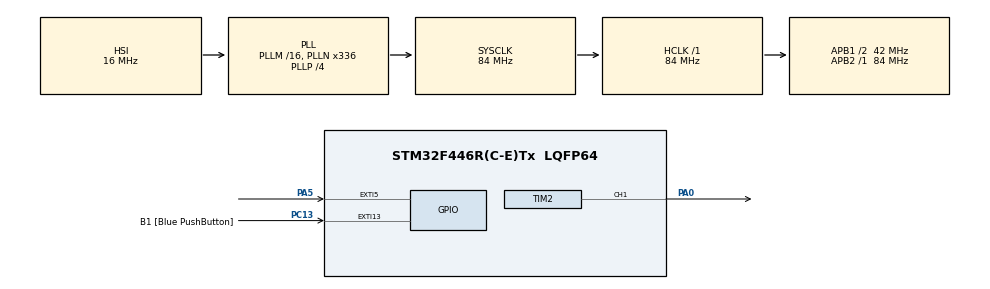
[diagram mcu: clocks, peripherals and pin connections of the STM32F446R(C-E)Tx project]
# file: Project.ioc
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Mcu.Family=STM32F4
Mcu.Name=STM32F446R(C-E)Tx
Mcu.Package=LQFP64
NVIC.PriorityGroup=NVIC_PRIORITYGROUP_0
PA0-WKUP.Signal=S_TIM2_CH1_ETR
PA13.GPIO_Label=TMS
PA13.Signal=SYS_JTMS-SWDIO
PA14.GPIO_Label=TCK
PA14.Signal=SYS_JTCK-SWCLK
PA2.GPIO_Label=USART_TX
PA2.Signal=USART2_TX
PA3.GPIO_Label=USART_RX
PA3.Signal=USART2_RX
PA5.Signal=GPXTI5
PB3.GPIO_Label=SWO
PB3.Signal=SYS_JTDO-SWO
PC13.GPIO_Label=B1 [Blue PushButton]
PC13.GPIO_ModeDefaultEXTI=GPIO_MODE_IT_FALLING
PC13.Signal=GPXTI13
PC14-OSC32_IN.Signal=RCC_OSC32_IN
PC15-OSC32_OUT.Signal=RCC_OSC32_OUT
PH0-OSC_IN.Mode=HSE-External-Oscillator
PH0-OSC_IN.Signal=RCC_OSC_IN
PH1-OSC_OUT.Mode=HSE-External-Oscillator
PH1-OSC_OUT.Signal=RCC_OSC_OUT
ProjectManager.HeapSize=0x200
ProjectManager.StackSize=0x400
ProjectManager.TargetToolchain=STM32CubeIDE
RCC.AHBFreq_Value=84000000
RCC.APB1CLKDivider=RCC_HCLK_DIV2
RCC.APB1Freq_Value=42000000
RCC.APB1TimFreq_Value=84000000
RCC.APB2Freq_Value=84000000
RCC.APB2TimFreq_Value=84000000
RCC.CortexFreq_Value=84000000
RCC.FLatency-AdvancedSettings=FLASH_LATENCY_2
RCC.HCLKFreq_Value=84000000
RCC.HSE_VALUE=8000000
RCC.HSI_VALUE=16000000
RCC.LSE_VALUE=32768
RCC.PLLN=336
RCC.PLLP=RCC_PLLP_DIV4
RCC.SYSCLKFreq_VALUE=84000000
RCC.SYSCLKSource=RCC_SYSCLKSOURCE_PLLCLK
RCC.USBFreq_Value=168000000
RCC.VCOOutputFreq_Value=336000000
SH.S_TIM2_CH1_ETR.0=TIM2_CH1,PWM Generation1 CH1
TIM2.AutoReloadPreload=TIM_AUTORELOAD_PRELOAD_ENABLE
TIM2.Channel-PWM\ Generation1\ CH1=TIM_CHANNEL_1
TIM2.Period=65535
VP_TIM2_VS_ClockSourceINT.Mode=Internal
board=NUCLEO-F446RE

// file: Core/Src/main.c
/* USER CODE BEGIN Header */
/**
 ******************************************************************************
 * @file           : main.c
 * @brief          : Main program body
 ******************************************************************************
 * @attention
 *
 * Copyright (c) 2024 STMicroelectronics.
 * All rights reserved.
 *
 * This software is licensed under terms that can be found in the LICENSE file
 * in the root directory of this software component.
 * If no LICENSE file comes with this software, it is provided AS-IS.
 *
 ******************************************************************************
 */
/* USER CODE END Header */
#include "main.h"

/* USER CODE BEGIN Includes */
#include <stdio.h>

/* USER CODE END Includes */

/* USER CODE BEGIN PTD */
#define BIP_PT 200 //BIP d'un point
#define BIP_TIRET 600//bip d'un tiret(Equiv 3 pts)*
#define ESC_ENTRE_LTR 600 //espacement entre 2 lettres
#define ESC_ENTRE_ELT 200 //espacement entre 2 element de la lettre
#define ESC_MOTS 1400 //espacement entre 2 mots = 7pts

/* USER CODE END PTD */

TIM_HandleTypeDef htim2;
char *morseCode[] = { "-.-.-----.", // !
		".-..-.", // "
		"..-..-.", // # (Na)
		"...-..-", // $
		"..-..-.", // % (Na)
		".-...", // &
		".----.", // '
		"-.--.", // (
		"-.--.-", // )
		"..-..-.", // * (Na)
		".-.-.", // +
		"--..--", // ,
		"-....-", // -
		".-.-.-", // .
		"-..-.", // /
		"-----", // 0
		".----", // 1
		"..---", // 2
		"...--", // 3
		"....-", // 4
		".....", // 5
		"-....", // 6
		"--...", // 7
		"---..", // 8
		"----.", // 9
		"---...", // :
		"-.-.-.", // ;
		".-..-.", // < (Na)
		"-...-", // =
		".-..-.", // > (Na)
		"..--..", // ?
		".--.-.", // @
		".-", // A
		"-...", // B
		"-.-.", // C
		"-..", // D
		".", // E
		"..-.", // F
		"--.", // G
		"....", // H
		"..", // I
		".---", // J
		"-.-", // K
		".-..", // L
		"--", // M
		"-.", // N
		"---", // O
		".--.", // P
		".-.", // Q
		".-.", // R
		"...", // S
		"-", // T
		"..-", // U
		"...-", // V
		".--", // W
		"-..-", // X
		"-.--", // Y
		"--..", // Z
		".-..-.", // [ (Na)
		".-..-.", // \ (Na)
		".-..-.", // ] (Na)
		".-..-.", // ^ (Na)
		"..--.-", // _
		".-..-.", // ` (Na)
		".-", // a
		"-...", // b
		"-.-.", // c
		"-..", // d
		".", // e
		"..-.", // f
		"--.", // g
		"....", // h
		"..", // i
		".---", // j
		"-.-", // k
		".-..", // l
		"--", // m
		"-.", // n
		"---", // o
		".--.", // p
		".-.", // q
		".-.", // r
		"...", // s
		"-", // t
		"..-", // u
		"...-", // v
		".--", // w
		"-..-", // x
		"-.--", // y
		"--..", // z
		};

void SystemClock_Config(void);
static void MX_GPIO_Init(void);
static void MX_TIM2_Init(void);
int conversion_ASCII(char caractere);
void interpretation(char c);

/* USER CODE BEGIN 0 */
uint8_t value = 0; // the value for the duty cycle

/* USER CODE END 0 */

int main(void) {

	/* MCU Configuration--------------------------------------------------------*/

	/* Reset of all peripherals, Initializes the Flash interface and the Systick. */
	HAL_Init();

	/* Configure the system clock */
	SystemClock_Config();

	/* Initialize all configured peripherals */
	MX_GPIO_Init();
	MX_TIM2_Init();
	/* USER CODE BEGIN 2 */
	HAL_TIM_PWM_Start(&htim2, TIM_CHANNEL_1);
	char *phrase = "ceci est un teste";
	/* USER CODE END 2 */

	/* Infinite loop */
	while (1) {
		for (int i = 0; phrase[i] != '\0'; i++) {
			interpretation(phrase[i]);
			HAL_Delay(ESC_ENTRE_LTR);
		}
		/* USER CODE BEGIN 3 */
	}

//
	/* USER CODE END 3 */
}

int conversion_ASCII(char caractere) {
	// Soustrait le code ASCII du caractère par le code ASCII du point d'exclamation ('!')
	// Cela permet de mapper les caractères ASCII à partir du point d'exclamation (33) au début du tableau codeMorse[]
	// Ainsi, '!' deviendra 0, et les caractères suivants seront convertis en valeurs croissantes
	return caractere - '!';
}
void interpretation(char c) {
	if (c == ' ') { //on a atteint la fin du mot
		htim2.Instance->CCR1 = 0; //on init a 0 pour arreter la génération de signaux sonores
		HAL_Delay(ESC_MOTS);
	} else {
		int index = conversion_ASCII(c); //on appelle la fct pour obtenir l'index du caractere dans le tableau
		char *morse = codeMorse[index]; //on recup la sequence la sequence de code morse du caractere
		for (int i = 0; morse[i] != '\0'; i++) { //\0 veux dire le caractere de fin de chaine(1er elt du code ASCII)
			if (morse[i] == '.') {
				htim2.Instance->CCR1 = 65535; // Active la sortie sonore
				HAL_Delay(BIP_PT); //On attends la durée correspondant a un point
				htim2.Instance->CCR1 = 0; // Désactive la sortie sonore
				HAL_Delay(ESC_ENTRE_ELT);
			} else if (morse[i] == '-') {
				htim2.Instance->CCR1 = 65535;
				HAL_Delay(BIP_TIRET);
				htim2.Instance->CCR1 = 0;
				HAL_Delay(ESC_ENTRE_ELT);
			}
		}
	}
}
void SystemClock_Config(void) {
	RCC_OscInitTypeDef RCC_OscInitStruct = { 0 };
	RCC_ClkInitTypeDef RCC_ClkInitStruct = { 0 };

	/** Configure the main internal regulator output voltage
	 */
	__HAL_RCC_PWR_CLK_ENABLE();
	__HAL_PWR_VOLTAGESCALING_CONFIG(PWR_REGULATOR_VOLTAGE_SCALE3);

	/** Initializes the RCC Oscillators according to the specified parameters
	 * in the RCC_OscInitTypeDef structure.
	 */
	RCC_OscInitStruct.OscillatorType = RCC_OSCILLATORTYPE_HSI;
	RCC_OscInitStruct.HSIState = RCC_HSI_ON;
	RCC_OscInitStruct.HSICalibrationValue = RCC_HSICALIBRATION_DEFAULT;
	RCC_OscInitStruct.PLL.PLLState = RCC_PLL_ON;
	RCC_OscInitStruct.PLL.PLLSource = RCC_PLLSOURCE_HSI;
	RCC_OscInitStruct.PLL.PLLM = 16;
	RCC_OscInitStruct.PLL.PLLN = 336;
	RCC_OscInitStruct.PLL.PLLP = RCC_PLLP_DIV4;
	RCC_OscInitStruct.PLL.PLLQ = 2;
	RCC_OscInitStruct.PLL.PLLR = 2;
	if (HAL_RCC_OscConfig(&RCC_OscInitStruct) != HAL_OK) {
		Error_Handler();
	}

	/** Initializes the CPU, AHB and APB buses clocks
	 */
	RCC_ClkInitStruct.ClockType = RCC_CLOCKTYPE_HCLK | RCC_CLOCKTYPE_SYSCLK
			| RCC_CLOCKTYPE_PCLK1 | RCC_CLOCKTYPE_PCLK2;
	RCC_ClkInitStruct.SYSCLKSource = RCC_SYSCLKSOURCE_PLLCLK;
	RCC_ClkInitStruct.AHBCLKDivider = RCC_SYSCLK_DIV1;
	RCC_ClkInitStruct.APB1CLKDivider = RCC_HCLK_DIV2;
	RCC_ClkInitStruct.APB2CLKDivider = RCC_HCLK_DIV1;

	if (HAL_RCC_ClockConfig(&RCC_ClkInitStruct, FLASH_LATENCY_2) != HAL_OK) {
		Error_Handler();
	}
}

static void MX_TIM2_Init(void) {

	TIM_ClockConfigTypeDef sClockSourceConfig = { 0 };
	TIM_MasterConfigTypeDef sMasterConfig = { 0 };
	TIM_OC_InitTypeDef sConfigOC = { 0 };

	htim2.Instance = TIM2;
	htim2.Init.Prescaler = 0;
	htim2.Init.CounterMode = TIM_COUNTERMODE_UP;
	htim2.Init.Period = 65535;
	htim2.Init.ClockDivision = TIM_CLOCKDIVISION_DIV1;
	htim2.Init.AutoReloadPreload = TIM_AUTORELOAD_PRELOAD_ENABLE;
	if (HAL_TIM_Base_Init(&htim2) != HAL_OK) {
		Error_Handler();
	}
	sClockSourceConfig.ClockSource = TIM_CLOCKSOURCE_INTERNAL;
	if (HAL_TIM_ConfigClockSource(&htim2, &sClockSourceConfig) != HAL_OK) {
		Error_Handler();
	}
	if (HAL_TIM_PWM_Init(&htim2) != HAL_OK) {
		Error_Handler();
	}
	sMasterConfig.MasterOutputTrigger = TIM_TRGO_RESET;
	sMasterConfig.MasterSlaveMode = TIM_MASTERSLAVEMODE_DISABLE;
	if (HAL_TIMEx_MasterConfigSynchronization(&htim2, &sMasterConfig)
			!= HAL_OK) {
		Error_Handler();
	}
	sConfigOC.OCMode = TIM_OCMODE_PWM1;
	sConfigOC.Pulse = 0;
	sConfigOC.OCPolarity = TIM_OCPOLARITY_HIGH;
	sConfigOC.OCFastMode = TIM_OCFAST_DISABLE;
	if (HAL_TIM_PWM_ConfigChannel(&htim2, &sConfigOC, TIM_CHANNEL_1)
			!= HAL_OK) {
		Error_Handler();
	}
	HAL_TIM_MspPostInit(&htim2);

}

static void MX_GPIO_Init(void) {
	GPIO_InitTypeDef GPIO_InitStruct = { 0 };

	/* GPIO Ports Clock Enable */
	__HAL_RCC_GPIOC_CLK_ENABLE();
	__HAL_RCC_GPIOH_CLK_ENABLE();
	__HAL_RCC_GPIOA_CLK_ENABLE();
	__HAL_RCC_GPIOB_CLK_ENABLE();

	/*Configure GPIO pin : B1_Pin */
	GPIO_InitStruct.Pin = B1_Pin;
	GPIO_InitStruct.Mode = GPIO_MODE_IT_FALLING;
	GPIO_InitStruct.Pull = GPIO_NOPULL;
	HAL_GPIO_Init(B1_GPIO_Port, &GPIO_InitStruct);

	/*Configure GPIO pins : USART_TX_Pin USART_RX_Pin */
	GPIO_InitStruct.Pin = USART_TX_Pin | USART_RX_Pin;
	GPIO_InitStruct.Mode = GPIO_MODE_AF_PP;
	GPIO_InitStruct.Pull = GPIO_NOPULL;
	GPIO_InitStruct.Speed = GPIO_SPEED_FREQ_VERY_HIGH;
	GPIO_InitStruct.Alternate = GPIO_AF7_USART2;
	HAL_GPIO_Init(GPIOA, &GPIO_InitStruct);

	/*Configure GPIO pin : PA5 */
	GPIO_InitStruct.Pin = GPIO_PIN_5;
	GPIO_InitStruct.Mode = GPIO_MODE_IT_RISING;
	GPIO_InitStruct.Pull = GPIO_NOPULL;
	HAL_GPIO_Init(GPIOA, &GPIO_InitStruct);

}

void Error_Handler(void) {
	__disable_irq();
	while (1) {
	}
}
